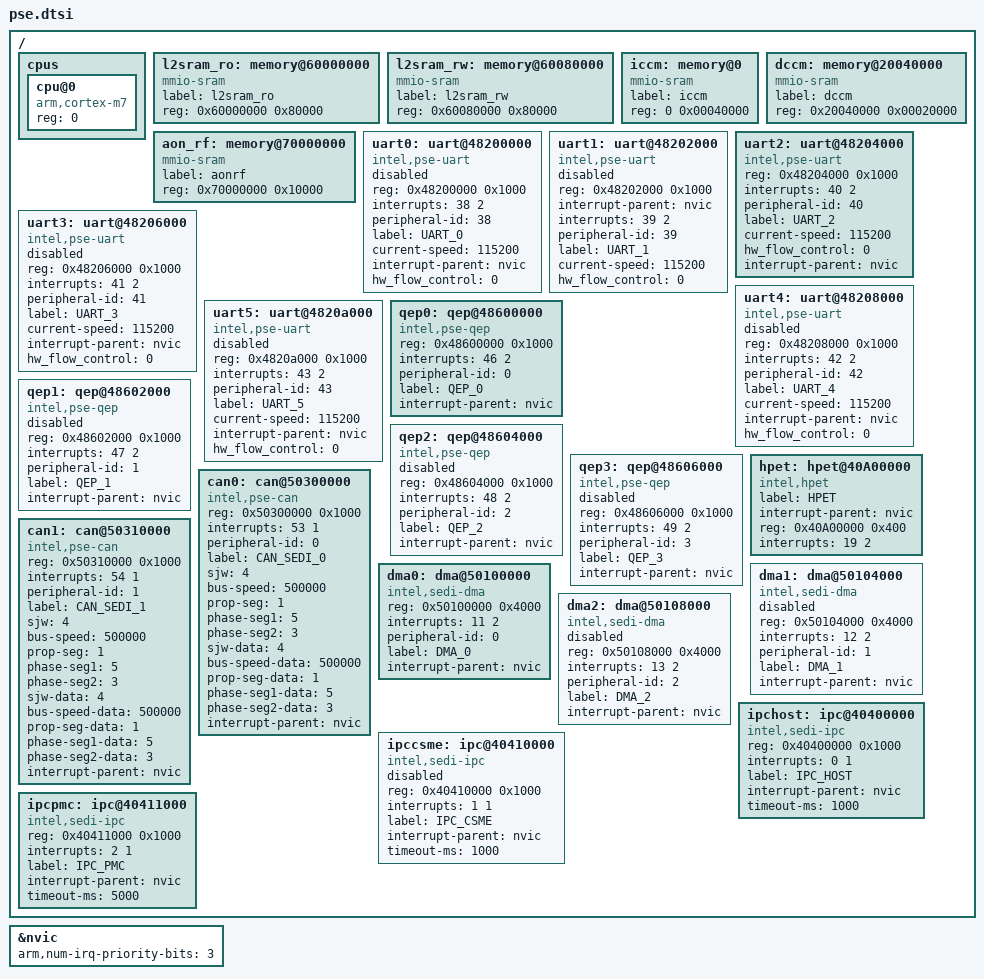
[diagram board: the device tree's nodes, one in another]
/*
 * Copyright (c) 2021 Intel Corporation
 *
 * SPDX-License-Identifier: Apache-2.0
 */

#include <arm/armv7-m.dtsi>
/ {
	cpus {
		#address-cells = <1>;
		#size-cells = <0>;

		cpu@0 {
			device_type = "cpu";
			compatible = "arm,cortex-m7";
			reg = <0>;
		};
	};

	l2sram_ro: memory@60000000{
		device_type = "memory";
		compatible = "mmio-sram";
		label = "l2sram_ro";
		reg = <0x60000000 0x80000>;
	};

	l2sram_rw: memory@60080000{
		device_type = "memory";
		compatible = "mmio-sram";
		label = "l2sram_rw";
		reg = <0x60080000 0x80000>;
	};

	iccm: memory@0{
		device_type = "memory";
		compatible = "mmio-sram";
		label = "iccm";
		reg = <0 0x00040000>;
	};

	dccm: memory@20040000{
		device_type = "memory";
		compatible = "mmio-sram";
		label = "dccm";
		reg = <0x20040000 0x00020000>;
	};

	aon_rf: memory@70000000{
		device_type = "memory";
		compatible = "mmio-sram";
		label = "aonrf";
		reg = <0x70000000 0x10000>;
	};

	uart0: uart@48200000 {
		compatible = "intel,pse-uart";
		reg = <0x48200000 0x1000>;
		interrupts = <38 2>;
		peripheral-id = <38>;
		label = "UART_0";
		current-speed = <115200>;
		interrupt-parent = <&nvic>;
		hw_flow_control = <0>;
		status = "disabled";
	};

	uart1: uart@48202000 {
		compatible = "intel,pse-uart";
		reg = <0x48202000 0x1000>;
		interrupt-parent = <&nvic>;
		interrupts = <39 2>;
		peripheral-id = <39>;
		label = "UART_1";
		current-speed = <115200>;
		hw_flow_control = <0>;
		status = "disabled";
	};

	uart2: uart@48204000 {
		compatible = "intel,pse-uart";
		reg = <0x48204000 0x1000>;
		interrupts = <40 2>;
		peripheral-id = <40>;
		label = "UART_2";
		current-speed = <115200>;
		hw_flow_control = <0>;
		interrupt-parent = <&nvic>;
		status = "okay";
	};

	uart3: uart@48206000 {
		compatible = "intel,pse-uart";
		reg = <0x48206000 0x1000>;
		interrupts = <41 2>;
		peripheral-id = <41>;
		label = "UART_3";
		current-speed = <115200>;
		interrupt-parent = <&nvic>;
		hw_flow_control = <0>;
		status = "disabled";
	};

	uart4: uart@48208000 {
		compatible = "intel,pse-uart";
		reg = <0x48208000 0x1000>;
		interrupts = <42 2>;
		peripheral-id = <42>;
		label = "UART_4";
		current-speed = <115200>;
		interrupt-parent = <&nvic>;
		hw_flow_control = <0>;
		status = "disabled";
	};

	uart5: uart@4820a000 {
		compatible = "intel,pse-uart";
		reg = <0x4820a000 0x1000>;
		interrupts = <43 2>;
		peripheral-id = <43>;
		label = "UART_5";
		current-speed = <115200>;
		interrupt-parent = <&nvic>;
		hw_flow_control = <0>;
		status = "disabled";
	};

	qep0: qep@48600000 {
		compatible = "intel,pse-qep";
		reg = <0x48600000 0x1000>;
		interrupts = <46 2>;
		peripheral-id = <0>;
		label = "QEP_0";
		interrupt-parent = <&nvic>;
		status = "okay";
	};

	qep1: qep@48602000 {
		compatible = "intel,pse-qep";
		reg = <0x48602000 0x1000>;
		interrupts = <47 2>;
		peripheral-id = <1>;
		label = "QEP_1";
		interrupt-parent = <&nvic>;
		status = "disabled";
	};

	qep2: qep@48604000 {
		compatible = "intel,pse-qep";
		reg = <0x48604000 0x1000>;
		interrupts = <48 2>;
		peripheral-id = <2>;
		label = "QEP_2";
		interrupt-parent = <&nvic>;
		status = "disabled";
	};

	qep3: qep@48606000 {
		compatible = "intel,pse-qep";
		reg = <0x48606000 0x1000>;
		interrupts = <49 2>;
		peripheral-id = <3>;
		label = "QEP_3";
		interrupt-parent = <&nvic>;
		status = "disabled";
	};

	hpet: hpet@40A00000{
		label = "HPET";
		compatible = "intel,hpet";
		interrupt-parent = <&nvic>;
		reg = <0x40A00000 0x400>;
		interrupts = <19 2>;
		status = "okay";
	};

	can0: can@50300000 {
		compatible = "intel,pse-can";
		#address-cells = <1>;
		#size-cells = <0>;
		reg = <0x50300000 0x1000>;
		interrupts = <53 1>;
		peripheral-id = <0>;
		label = "CAN_SEDI_0";
		sjw = <4>;
		bus-speed = <500000>;
		prop-seg = <1>;
		phase-seg1 = <5>;
		phase-seg2 = <3>;
		sjw-data = <4>;
		bus-speed-data = <500000>;
		prop-seg-data = <1>;
		phase-seg1-data = <5>;
		phase-seg2-data = <3>;
		interrupt-parent = <&nvic>;
		status = "okay";
	};

	can1: can@50310000 {
		compatible = "intel,pse-can";
		#address-cells = <1>;
		#size-cells = <0>;
		reg = <0x50310000 0x1000>;
		interrupts = <54 1>;
		peripheral-id = <1>;
		label = "CAN_SEDI_1";
		sjw = <4>;
		bus-speed = <500000>;
		prop-seg = <1>;
		phase-seg1 = <5>;
		phase-seg2 = <3>;
		sjw-data = <4>;
		bus-speed-data = <500000>;
		prop-seg-data = <1>;
		phase-seg1-data = <5>;
		phase-seg2-data = <3>;
		interrupt-parent = <&nvic>;
		status = "okay";
	};
	dma0: dma@50100000 {
		compatible = "intel,sedi-dma";
		#dma-cells = <8>;
		reg = <0x50100000 0x4000>;
		interrupts = <11 2>;
		peripheral-id = <0>;
		label = "DMA_0";
		interrupt-parent = <&nvic>;
		status = "okay";
	};
	dma1: dma@50104000 {
		compatible = "intel,sedi-dma";
		#dma-cells = <8>;
		reg = <0x50104000 0x4000>;
		interrupts = <12 2>;
		peripheral-id = <1>;
		label = "DMA_1";
		interrupt-parent = <&nvic>;
		status = "disabled";
	};
	dma2: dma@50108000 {
		compatible = "intel,sedi-dma";
		#dma-cells = <8>;
		reg = <0x50108000 0x4000>;
		interrupts = <13 2>;
		peripheral-id = <2>;
		label = "DMA_2";
		interrupt-parent = <&nvic>;
		status = "disabled";
	};
	ipchost: ipc@40400000 {
		compatible = "intel,sedi-ipc";
		reg = <0x40400000 0x1000>;
		interrupts = <0 1>;
		label = "IPC_HOST";
		interrupt-parent = <&nvic>;
		timeout-ms = <1000>;
		status = "okay";
	};
	ipccsme: ipc@40410000 {
		compatible = "intel,sedi-ipc";
		reg = <0x40410000 0x1000>;
		interrupts = <1 1>;
		label = "IPC_CSME";
		interrupt-parent = <&nvic>;
		timeout-ms = <1000>;
		status = "disabled";
	};
	ipcpmc: ipc@40411000 {
		compatible = "intel,sedi-ipc";
		reg = <0x40411000 0x1000>;
		interrupts = <2 1>;
		label = "IPC_PMC";
		interrupt-parent = <&nvic>;
		timeout-ms = <5000>;
		status = "okay";
	};
};

&nvic {
	arm,num-irq-priority-bits = <3>;
};
